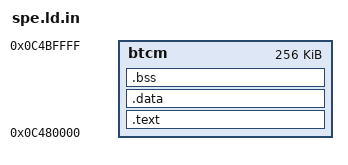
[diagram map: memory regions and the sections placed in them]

MEMORY
{
  btcm  : ORIGIN = 206045184, LENGTH = 262144
}

FIQ_SIZE = 0x300;
IRQ_SIZE = 0x300;
ABT_SIZE = 0x100;
UND_SIZE = 0x100;
SVC_SIZE = 0x300;

_estack = 206045184 + 262144;
_fiqstack = _estack;
_irqstack = _fiqstack - FIQ_SIZE;
_abtstack = _irqstack - IRQ_SIZE;
_undstack = _abtstack - ABT_SIZE;
_svcstack = _undstack - UND_SIZE;
_sstack =  _svcstack - SVC_SIZE;

_heap_end = _sstack;

SECTIONS
{
    .text :
    {
        . = ALIGN(4);
	_stext = .;
	KEEP(*(.vectors .vectors.*))
        . = ALIGN(4);
        *(.text .text.*)
        *(.rodata .rodata*)
        . = ALIGN(4);
        _etext = .;
    } > btcm

    .data :
    {
        _sdata = .;
        *(.data .data.*);
        . = ALIGN(4);
        _edata = .;
    } > btcm

    .bss :
    {
        _sbss = . ;
        *(.bss .bss.*)
        *(COMMON)
        . = ALIGN(4);
        _ebss = . ;
    } > btcm
    _end = . ;

    . = ALIGN(4);
    _heap_start = .;
}
